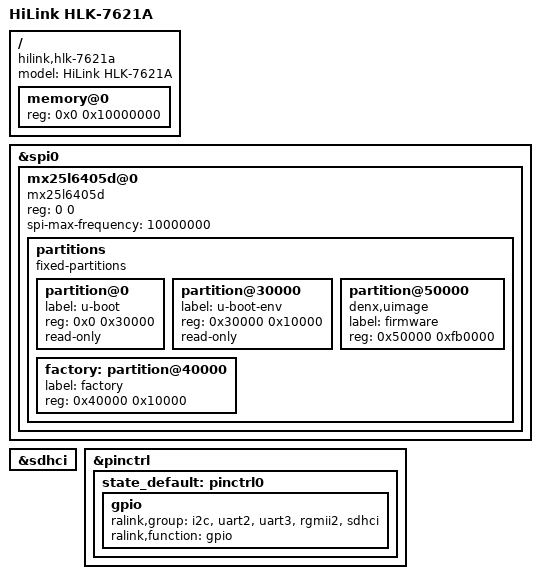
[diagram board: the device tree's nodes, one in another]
// SPDX-License-Identifier: GPL-2.0-or-later

#include "mt7621.dtsi"

#include <dt-bindings/gpio/gpio.h>
#include <dt-bindings/input/input.h>

/ {
	compatible = "hilink,hlk-7621a", "mediatek,mt7621-soc";
	model = "HiLink HLK-7621A";

	memory@0 {
		device_type = "memory";
		reg = <0x0 0x10000000>;
	};
};

&spi0 {
    status = "okay";

    mx25l6405d@0 {
        compatible = "mx25l6405d","jedec,spi-nor";
        reg = <0 0>;
        spi-max-frequency = <10000000>;

        partitions {
            compatible = "fixed-partitions";
            #address-cells = <1>;
            #size-cells = <1>;

            partition@0 {
                label = "u-boot";
                reg = <0x0 0x30000>;
                read-only;
            };

            partition@30000 {
                label = "u-boot-env";
                reg = <0x30000 0x10000>;
                read-only;
            };

            factory: partition@40000 {
                label = "factory";
                reg = <0x40000 0x10000>;
                /*read-only;*/
            };

            partition@50000 {
                compatible = "denx,uimage";
                label = "firmware";
                reg = <0x50000 0xfb0000>;
            };
        };
    };
};


&sdhci {
	status = "okay";
};

&pinctrl {
	state_default: pinctrl0 {
		gpio {
			ralink,group = "i2c", "uart2", "uart3", "rgmii2", "sdhci";
			ralink,function = "gpio";
		};
	};
};
